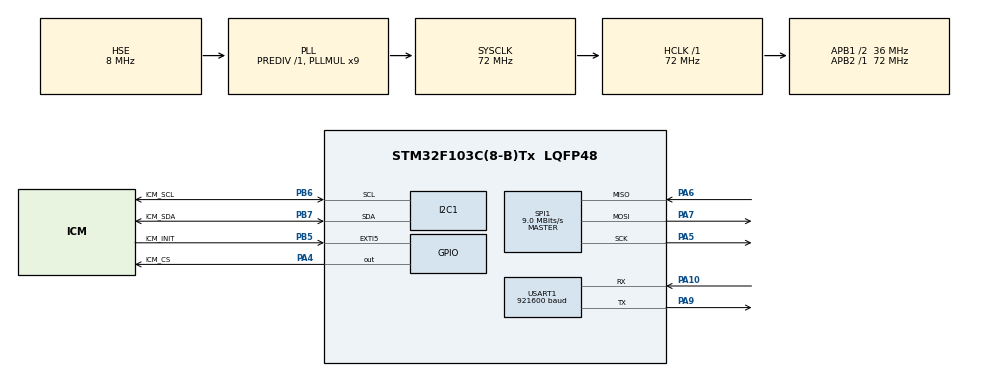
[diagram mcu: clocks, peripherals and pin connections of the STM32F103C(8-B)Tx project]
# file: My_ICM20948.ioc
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Mcu.Family=STM32F1
Mcu.Name=STM32F103C(8-B)Tx
Mcu.Package=LQFP48
NVIC.EXTI9_5_IRQn=true\:1\:0\:true\:false\:true\:true\:true
NVIC.PriorityGroup=NVIC_PRIORITYGROUP_4
PA10.Mode=Asynchronous
PA10.Signal=USART1_RX
PA13.Mode=Serial_Wire
PA13.Signal=SYS_JTMS-SWDIO
PA14.Mode=Serial_Wire
PA14.Signal=SYS_JTCK-SWCLK
PA4.GPIO_Label=ICM_CS
PA4.Signal=GPIO_Output
PA5.Mode=Full_Duplex_Master
PA5.Signal=SPI1_SCK
PA6.Mode=Full_Duplex_Master
PA6.Signal=SPI1_MISO
PA7.Mode=Full_Duplex_Master
PA7.Signal=SPI1_MOSI
PA9.Mode=Asynchronous
PA9.Signal=USART1_TX
PB5.GPIO_Label=ICM_INIT
PB5.GPIO_PuPd=GPIO_PULLDOWN
PB5.Signal=GPXTI5
PB6.GPIO_Label=ICM_SCL
PB6.Mode=I2C
PB6.Signal=I2C1_SCL
PB7.GPIO_Label=ICM_SDA
PB7.Mode=I2C
PB7.Signal=I2C1_SDA
PD0-OSC_IN.Mode=HSE-External-Oscillator
PD0-OSC_IN.Signal=RCC_OSC_IN
PD1-OSC_OUT.Mode=HSE-External-Oscillator
PD1-OSC_OUT.Signal=RCC_OSC_OUT
ProjectManager.HeapSize=0x200
ProjectManager.StackSize=0x400
ProjectManager.TargetToolchain=MDK-ARM V5.27
RCC.AHBFreq_Value=72000000
RCC.APB1CLKDivider=RCC_HCLK_DIV2
RCC.APB1Freq_Value=36000000
RCC.APB1TimFreq_Value=72000000
RCC.APB2Freq_Value=72000000
RCC.APB2TimFreq_Value=72000000
RCC.HCLKFreq_Value=72000000
RCC.PLLMUL=RCC_PLL_MUL9
RCC.PLLSourceVirtual=RCC_PLLSOURCE_HSE
RCC.SYSCLKFreq_VALUE=72000000
RCC.SYSCLKSource=RCC_SYSCLKSOURCE_PLLCLK
RCC.USBFreq_Value=72000000
SPI1.BaudRatePrescaler=SPI_BAUDRATEPRESCALER_8
SPI1.CalculateBaudRate=9.0 MBits/s
SPI1.Direction=SPI_DIRECTION_2LINES
SPI1.Mode=SPI_MODE_MASTER
SPI1.VirtualType=VM_MASTER
USART1.BaudRate=921600
USART1.VirtualMode=VM_ASYNC
board=custom

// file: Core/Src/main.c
/* USER CODE BEGIN Header */
/**
  ******************************************************************************
  * @file           : main.c
  * @brief          : Main program body
  ******************************************************************************
  * @attention
  *
  * <h2><center>&copy; Copyright (c) 2025 STMicroelectronics.
  * All rights reserved.</center></h2>
  *
  * This software component is licensed by ST under BSD 3-Clause license,
  * the "License"; You may not use this file except in compliance with the
  * License. You may obtain a copy of the License at:
  *                        opensource.org/licenses/BSD-3-Clause
  *
  ******************************************************************************
  */
/* USER CODE END Header */
#include "main.h"
#include "i2c.h"
#include "spi.h"
#include "usart.h"
#include "gpio.h"

/* USER CODE BEGIN Includes */
#include "icm20948.h"
/* USER CODE END Includes */

void SystemClock_Config(void);

int main(void)
{
  /* USER CODE BEGIN 1 */
	uint8_t res = 0;
  /* USER CODE END 1 */

  /* MCU Configuration--------------------------------------------------------*/

  /* Reset of all peripherals, Initializes the Flash interface and the Systick. */
  HAL_Init();

  /* Configure the system clock */
  SystemClock_Config();

  /* Initialize all configured peripherals */
  MX_GPIO_Init();
  MX_I2C1_Init();
  MX_SPI1_Init();
  MX_USART1_UART_Init();
  /* USER CODE BEGIN 2 */
	printf("start init1\r\n");
  /* USER CODE END 2 */
	 uint8_t addr = 0;
//chooseIMUChannel(0x01);
 HAL_I2C_Mem_Read(&hi2c1, (0X68 << 1 | 0x01), 0x00, 1, &addr, 1, 10);

    HAL_I2C_Mem_Read(&hi2c1, (0X68 << 1 | 0x01), 0x00, 1, &addr, 1, 10);
    printf("addr ID %x\r\n", addr);
    addr = 0;

  printf("%x\r\n", res);
  /* Infinite loop */
  while (1)
  {

  }
}

void SystemClock_Config(void)
{
  RCC_OscInitTypeDef RCC_OscInitStruct = {0};
  RCC_ClkInitTypeDef RCC_ClkInitStruct = {0};

  /** Initializes the RCC Oscillators according to the specified parameters
  * in the RCC_OscInitTypeDef structure.
  */
  RCC_OscInitStruct.OscillatorType = RCC_OSCILLATORTYPE_HSE;
  RCC_OscInitStruct.HSEState = RCC_HSE_ON;
  RCC_OscInitStruct.HSEPredivValue = RCC_HSE_PREDIV_DIV1;
  RCC_OscInitStruct.HSIState = RCC_HSI_ON;
  RCC_OscInitStruct.PLL.PLLState = RCC_PLL_ON;
  RCC_OscInitStruct.PLL.PLLSource = RCC_PLLSOURCE_HSE;
  RCC_OscInitStruct.PLL.PLLMUL = RCC_PLL_MUL9;
  if (HAL_RCC_OscConfig(&RCC_OscInitStruct) != HAL_OK)
  {
    Error_Handler();
  }
  /** Initializes the CPU, AHB and APB buses clocks
  */
  RCC_ClkInitStruct.ClockType = RCC_CLOCKTYPE_HCLK|RCC_CLOCKTYPE_SYSCLK
                              |RCC_CLOCKTYPE_PCLK1|RCC_CLOCKTYPE_PCLK2;
  RCC_ClkInitStruct.SYSCLKSource = RCC_SYSCLKSOURCE_PLLCLK;
  RCC_ClkInitStruct.AHBCLKDivider = RCC_SYSCLK_DIV1;
  RCC_ClkInitStruct.APB1CLKDivider = RCC_HCLK_DIV2;
  RCC_ClkInitStruct.APB2CLKDivider = RCC_HCLK_DIV1;

  if (HAL_RCC_ClockConfig(&RCC_ClkInitStruct, FLASH_LATENCY_2) != HAL_OK)
  {
    Error_Handler();
  }
}

void Error_Handler(void)
{
}

/************************ (C) COPYRIGHT STMicroelectronics *****END OF FILE****/
